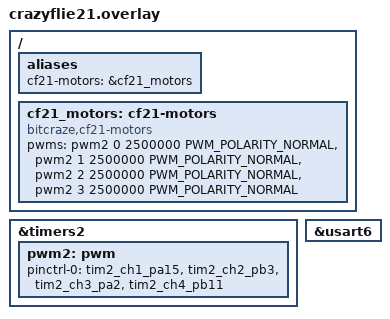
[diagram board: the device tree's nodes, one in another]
/*
 * crazyflie21.overlay — Tapestry DTS overlay for Crazyflie 2.1 brushless
 *
 * Applied on top of tapestry-scr-hw/boards/bitcraze/crazyflie21/crazyflie21.dts.
 *
 * Hardware: STM32F405RGT6, 168 MHz, FPU
 * Motor ESC protocol: RC PWM at 400 Hz (2500 µs period)
 *   1000 µs = armed / idle
 *   2000 µs = full throttle
 *
 * Motor layout (from above):
 *   M4(CW)  M1(CCW)   ← front
 *   M3(CW)  M2(CCW)   ← back
 *
 * TODO: verify all pin assignments (marked below) against the CF2.1
 *       brushless schematic before flashing real hardware:
 *   https://www.bitcraze.io/documentation/hardware/crazyflie_2_1/
 */

/ {
    aliases {
        cf21-motors = &cf21_motors;
    };

    cf21_motors: cf21-motors {
        compatible = "bitcraze,cf21-motors";
        /*
         * Four ESC PWM channels in M1..M4 order.
         * Period = 2 500 000 ns (400 Hz).  All four channels share TIM2.
         */
        pwms = <&pwm2 0 2500000 PWM_POLARITY_NORMAL>,  /* M1 front-right CCW */
               <&pwm2 1 2500000 PWM_POLARITY_NORMAL>,  /* M2 back-right  CCW */
               <&pwm2 2 2500000 PWM_POLARITY_NORMAL>,  /* M3 back-left   CW  */
               <&pwm2 3 2500000 PWM_POLARITY_NORMAL>;  /* M4 front-left  CW  */
    };
};

&timers2 {
    status = "okay";

    pwm2: pwm {
        status = "okay";
        /*
         * Pin assignments — TODO: verify channel numbers and GPIO pins
         * against the Crazyflie 2.1 brushless schematic.
         *
         * Tentative mapping (Crazyflie 2.x motor deck):
         *   TIM2_CH1 → PA15   M1 front-right
         *   TIM2_CH2 → PB3    M2 back-right
         *   TIM2_CH3 → PA2    M3 back-left
         *   TIM2_CH4 → PB11   M4 front-left
         */
        pinctrl-0 = <
            &tim2_ch1_pa15   /* M1 front-right — TODO verify vs schematic */
            &tim2_ch2_pb3    /* M2 back-right  — TODO verify vs schematic */
            &tim2_ch3_pa2    /* M3 back-left   — TODO verify vs schematic */
            &tim2_ch4_pb11   /* M4 front-left  — TODO verify vs schematic */
        >;
        pinctrl-names = "default";
    };
};

/*
 * nRF51822 BLE radio co-processor.
 *
 * The nRF51 is wired to USART6 (PC6/PC7) on the STM32F405.
 * Enabled here so the UART is clocked and configured; the Zephyr BT stack
 * binds to it when CONFIG_BT_HCI_UART=y (see crazyflie21.conf).
 *
 * PREREQUISITE: the nRF51 must be reflashed with HCI firmware before BLE
 * works.  The factory firmware uses a proprietary CRTP protocol, not HCI.
 * Use Nordic's open-source hci_uart sample from nRF5 SDK, or Zephyr's
 * own hci_uart application, built for nRF51822.
 *
 * TODO: verify USART6 PC6/PC7 against CF2.1 schematic.
 */
&usart6 {
    status = "okay";
};
